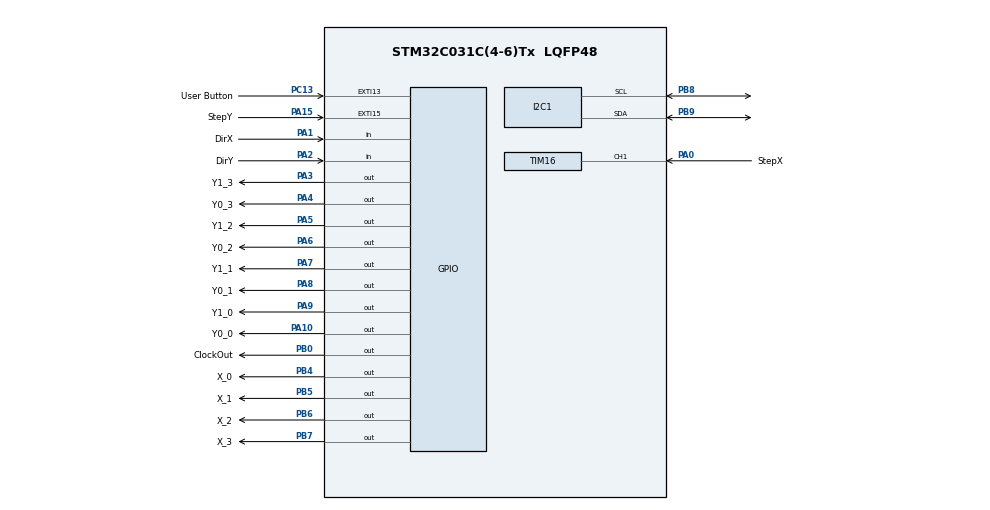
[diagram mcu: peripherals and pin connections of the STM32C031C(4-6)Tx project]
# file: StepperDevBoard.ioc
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I2C1.CustomTiming=Disabled
I2C1.NoStretchMode=I2C_NOSTRETCH_ENABLE
I2C1.OwnAddress=15
I2C1.Timing=0x20303E5D
Mcu.Family=STM32C0
Mcu.Name=STM32C031C(4-6)Tx
Mcu.Package=LQFP48
NVIC.EXTI4_15_IRQn=true\:0\:0\:false\:false\:true\:true\:true\:true
NVIC.I2C1_IRQn=true\:0\:0\:false\:false\:true\:true\:true\:true
NVIC.TIM14_IRQn=true\:0\:0\:false\:false\:true\:true\:true\:true
NVIC.TIM16_IRQn=true\:0\:0\:false\:false\:true\:true\:true\:true
PA0.GPIO_Label=StepX
PA0.GPIO_PuPd=GPIO_NOPULL
PA0.Signal=S_TIM16_CH1
PA1.GPIO_Label=DirX
PA1.Signal=GPIO_Input
PA10.GPIO_Label=Y0_0
PA10.GPIO_Speed=GPIO_SPEED_FREQ_HIGH
PA10.Signal=GPIO_Output
PA13.GPIO_Label=SWDIO
PA13.Mode=Serial_Wire
PA13.Signal=DEBUG_SWDIO
PA14-BOOT0.GPIO_Label=SWCLK
PA14-BOOT0.Mode=Serial_Wire
PA14-BOOT0.Signal=DEBUG_SWCLK
PA15.GPIO_Label=StepY
PA15.Signal=GPXTI15
PA2.GPIO_Label=DirY
PA2.Signal=GPIO_Input
PA3.GPIO_Label=Y1_3
PA3.GPIO_Speed=GPIO_SPEED_FREQ_HIGH
PA3.Signal=GPIO_Output
PA4.GPIO_Label=Y0_3
PA4.GPIO_Speed=GPIO_SPEED_FREQ_HIGH
PA4.Signal=GPIO_Output
PA5.GPIO_Label=Y1_2
PA5.GPIO_Speed=GPIO_SPEED_FREQ_HIGH
PA5.PinState=GPIO_PIN_RESET
PA5.Signal=GPIO_Output
PA6.GPIO_Label=Y0_2
PA6.GPIO_Speed=GPIO_SPEED_FREQ_HIGH
PA6.Signal=GPIO_Output
PA7.GPIO_Label=Y1_1
PA7.GPIO_Speed=GPIO_SPEED_FREQ_HIGH
PA7.Signal=GPIO_Output
PA8.GPIO_Label=Y0_1
PA8.GPIO_Speed=GPIO_SPEED_FREQ_HIGH
PA8.Signal=GPIO_Output
PA9.GPIO_Label=Y1_0
PA9.GPIO_Speed=GPIO_SPEED_FREQ_HIGH
PA9.Signal=GPIO_Output
PB0.GPIO_Label=ClockOut
PB0.Signal=GPIO_Output
PB4.GPIO_Label=X_0
PB4.GPIO_Speed=GPIO_SPEED_FREQ_HIGH
PB4.Signal=GPIO_Output
PB5.GPIO_Label=X_1
PB5.GPIO_Speed=GPIO_SPEED_FREQ_HIGH
PB5.Signal=GPIO_Output
PB6.GPIO_Label=X_2
PB6.GPIO_Speed=GPIO_SPEED_FREQ_HIGH
PB6.Signal=GPIO_Output
PB7.GPIO_Label=X_3
PB7.GPIO_Speed=GPIO_SPEED_FREQ_HIGH
PB7.Signal=GPIO_Output
PB8.GPIO_Pu=GPIO_NOPULL
PB8.GPIO_Speed=GPIO_SPEED_FREQ_HIGH
PB8.Mode=I2C
PB8.Signal=I2C1_SCL
PB9.GPIO_Pu=GPIO_NOPULL
PB9.GPIO_Speed=GPIO_SPEED_FREQ_HIGH
PB9.Mode=I2C
PB9.Signal=I2C1_SDA
PC13.GPIO_Label=User Button
PC13.Signal=GPXTI13
PC14-OSCX_IN\ (PC14).Mode=LSE-External-Oscillator
PC14-OSCX_IN\ (PC14).Signal=RCC_OSCX_IN
PC15-OSCX_OUT\ (PC15).Mode=LSE-External-Oscillator
PC15-OSCX_OUT\ (PC15).Signal=RCC_OSCX_OUT
PF0-OSC_IN\ (PF0).Mode=HSE-External-Oscillator
PF0-OSC_IN\ (PF0).Signal=RCC_OSC_IN
PF1-OSC_OUT\ (PF1).Mode=HSE-External-Oscillator
PF1-OSC_OUT\ (PF1).Signal=RCC_OSC_OUT
ProjectManager.HeapSize=0x200
ProjectManager.StackSize=0x400
ProjectManager.TargetToolchain=STM32CubeIDE
RCC.ADCFreq_Value=48000000
RCC.AHBFreq_Value=48000000
RCC.CortexFreq_Value=48000000
RCC.EXTERNAL_CLOCK_VALUE=12288000
RCC.HCLKFreq_Value=48000000
RCC.HSE_VALUE=48000000
RCC.HSISYSCLKDivider=RCC_HSI_DIV1
RCC.HSI_VALUE=48000000
RCC.SYSCLKFreq_VALUE=48000000
SH.S_TIM16_CH1.0=TIM16_CH1,Input_Capture1_from_TI1
TIM14.AutoReloadPreload=TIM_AUTORELOAD_PRELOAD_DISABLE
TIM14.ClockDivision=TIM_CLOCKDIVISION_DIV1
TIM14.Period=38400-1
TIM14.Prescaler=2-1
TIM16.Channel=TIM_CHANNEL_1
TIM16.ICPolarity_CH1=TIM_INPUTCHANNELPOLARITY_BOTHEDGE
TIM16.Prescaler=48-1
VP_TIM14_VS_ClockSourceINT.Mode=Enable_Timer
VP_TIM16_VS_ClockSourceINT.Mode=Enable_Timer
board=NUCLEO-C031C6

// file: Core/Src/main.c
/* USER CODE BEGIN Header */
/**
  ******************************************************************************
  * @file           : main.c
  * @brief          : Main program body
  ******************************************************************************
  * @attention
  *
  * Copyright (c) 2024 STMicroelectronics.
  * All rights reserved.
  *
  * This software is licensed under terms that can be found in the LICENSE file
  * in the root directory of this software component.
  * If no LICENSE file comes with this software, it is provided AS-IS.
  *
  ******************************************************************************
  */
/* USER CODE END Header */
#include "main.h"

I2C_HandleTypeDef hi2c1;

TIM_HandleTypeDef htim14;
TIM_HandleTypeDef htim16;

void SystemClock_Config(void);
static void MX_GPIO_Init(void);
static void MX_I2C1_Init(void);
static void MX_TIM14_Init(void);
static void MX_TIM16_Init(void);
/* USER CODE BEGIN PFP */
void mazeMain(void);
/* USER CODE END PFP */

int main(void)
{

  /* MCU Configuration--------------------------------------------------------*/

  /* Reset of all peripherals, Initializes the Flash interface and the Systick. */
  HAL_Init();

  /* Configure the system clock */
  SystemClock_Config();

  /* Initialize all configured peripherals */
  MX_GPIO_Init();
  MX_I2C1_Init();
  MX_TIM14_Init();
  MX_TIM16_Init();
  /* USER CODE BEGIN 2 */
  mazeMain();
  /* USER CODE END 2 */

  /* Infinite loop */
  while (1)
  {

  }
}

void SystemClock_Config(void)
{
  RCC_OscInitTypeDef RCC_OscInitStruct = {0};
  RCC_ClkInitTypeDef RCC_ClkInitStruct = {0};

  /** Initializes the RCC Oscillators according to the specified parameters
  * in the RCC_OscInitTypeDef structure.
  */
  RCC_OscInitStruct.OscillatorType = RCC_OSCILLATORTYPE_HSI;
  RCC_OscInitStruct.HSIState = RCC_HSI_ON;
  RCC_OscInitStruct.HSIDiv = RCC_HSI_DIV1;
  RCC_OscInitStruct.HSICalibrationValue = RCC_HSICALIBRATION_DEFAULT;
  if (HAL_RCC_OscConfig(&RCC_OscInitStruct) != HAL_OK)
  {
    Error_Handler();
  }

  /** Initializes the CPU, AHB and APB buses clocks
  */
  RCC_ClkInitStruct.ClockType = RCC_CLOCKTYPE_HCLK|RCC_CLOCKTYPE_SYSCLK
                              |RCC_CLOCKTYPE_PCLK1;
  RCC_ClkInitStruct.SYSCLKSource = RCC_SYSCLKSOURCE_HSI;
  RCC_ClkInitStruct.SYSCLKDivider = RCC_SYSCLK_DIV1;
  RCC_ClkInitStruct.AHBCLKDivider = RCC_HCLK_DIV1;
  RCC_ClkInitStruct.APB1CLKDivider = RCC_APB1_DIV1;

  if (HAL_RCC_ClockConfig(&RCC_ClkInitStruct, FLASH_LATENCY_1) != HAL_OK)
  {
    Error_Handler();
  }
}

static void MX_I2C1_Init(void)
{

  hi2c1.Instance = I2C1;
  hi2c1.Init.Timing = 0x20303E5D;
  hi2c1.Init.OwnAddress1 = 30;
  hi2c1.Init.AddressingMode = I2C_ADDRESSINGMODE_7BIT;
  hi2c1.Init.DualAddressMode = I2C_DUALADDRESS_DISABLE;
  hi2c1.Init.OwnAddress2 = 0;
  hi2c1.Init.OwnAddress2Masks = I2C_OA2_NOMASK;
  hi2c1.Init.GeneralCallMode = I2C_GENERALCALL_DISABLE;
  hi2c1.Init.NoStretchMode = I2C_NOSTRETCH_ENABLE;
  if (HAL_I2C_Init(&hi2c1) != HAL_OK)
  {
    Error_Handler();
  }

  /** Configure Analogue filter
  */
  if (HAL_I2CEx_ConfigAnalogFilter(&hi2c1, I2C_ANALOGFILTER_ENABLE) != HAL_OK)
  {
    Error_Handler();
  }

  /** Configure Digital filter
  */
  if (HAL_I2CEx_ConfigDigitalFilter(&hi2c1, 0) != HAL_OK)
  {
    Error_Handler();
  }

}

static void MX_TIM14_Init(void)
{

  htim14.Instance = TIM14;
  htim14.Init.Prescaler = 2-1;
  htim14.Init.CounterMode = TIM_COUNTERMODE_UP;
  htim14.Init.Period = 38400-1;
  htim14.Init.ClockDivision = TIM_CLOCKDIVISION_DIV1;
  htim14.Init.AutoReloadPreload = TIM_AUTORELOAD_PRELOAD_DISABLE;
  if (HAL_TIM_Base_Init(&htim14) != HAL_OK)
  {
    Error_Handler();
  }

}

static void MX_TIM16_Init(void)
{

  TIM_IC_InitTypeDef sConfigIC = {0};

  htim16.Instance = TIM16;
  htim16.Init.Prescaler = 48-1;
  htim16.Init.CounterMode = TIM_COUNTERMODE_UP;
  htim16.Init.Period = 65535;
  htim16.Init.ClockDivision = TIM_CLOCKDIVISION_DIV1;
  htim16.Init.RepetitionCounter = 0;
  htim16.Init.AutoReloadPreload = TIM_AUTORELOAD_PRELOAD_DISABLE;
  if (HAL_TIM_Base_Init(&htim16) != HAL_OK)
  {
    Error_Handler();
  }
  if (HAL_TIM_IC_Init(&htim16) != HAL_OK)
  {
    Error_Handler();
  }
  sConfigIC.ICPolarity = TIM_INPUTCHANNELPOLARITY_BOTHEDGE;
  sConfigIC.ICSelection = TIM_ICSELECTION_DIRECTTI;
  sConfigIC.ICPrescaler = TIM_ICPSC_DIV1;
  sConfigIC.ICFilter = 0;
  if (HAL_TIM_IC_ConfigChannel(&htim16, &sConfigIC, TIM_CHANNEL_1) != HAL_OK)
  {
    Error_Handler();
  }

}

static void MX_GPIO_Init(void)
{
  GPIO_InitTypeDef GPIO_InitStruct = {0};

  /* GPIO Ports Clock Enable */
  __HAL_RCC_GPIOC_CLK_ENABLE();
  __HAL_RCC_GPIOF_CLK_ENABLE();
  __HAL_RCC_GPIOA_CLK_ENABLE();
  __HAL_RCC_GPIOB_CLK_ENABLE();

  /*Configure GPIO pin Output Level */
  HAL_GPIO_WritePin(GPIOA, Y1_3_Pin|Y0_3_Pin|Y1_2_Pin|Y0_2_Pin
                          |Y1_1_Pin|Y0_1_Pin|Y1_0_Pin|Y0_0_Pin, GPIO_PIN_RESET);

  /*Configure GPIO pin Output Level */
  HAL_GPIO_WritePin(GPIOB, ClockOut_Pin|X_0_Pin|X_1_Pin|X_2_Pin
                          |X_3_Pin, GPIO_PIN_RESET);

  /*Configure GPIO pin : User_Button_Pin */
  GPIO_InitStruct.Pin = User_Button_Pin;
  GPIO_InitStruct.Mode = GPIO_MODE_IT_RISING;
  GPIO_InitStruct.Pull = GPIO_NOPULL;
  HAL_GPIO_Init(User_Button_GPIO_Port, &GPIO_InitStruct);

  /*Configure GPIO pins : DirX_Pin DirY_Pin */
  GPIO_InitStruct.Pin = DirX_Pin|DirY_Pin;
  GPIO_InitStruct.Mode = GPIO_MODE_INPUT;
  GPIO_InitStruct.Pull = GPIO_NOPULL;
  HAL_GPIO_Init(GPIOA, &GPIO_InitStruct);

  /*Configure GPIO pins : Y1_3_Pin Y0_3_Pin Y1_2_Pin Y0_2_Pin
                           Y1_1_Pin Y0_1_Pin Y1_0_Pin Y0_0_Pin */
  GPIO_InitStruct.Pin = Y1_3_Pin|Y0_3_Pin|Y1_2_Pin|Y0_2_Pin
                          |Y1_1_Pin|Y0_1_Pin|Y1_0_Pin|Y0_0_Pin;
  GPIO_InitStruct.Mode = GPIO_MODE_OUTPUT_PP;
  GPIO_InitStruct.Pull = GPIO_NOPULL;
  GPIO_InitStruct.Speed = GPIO_SPEED_FREQ_HIGH;
  HAL_GPIO_Init(GPIOA, &GPIO_InitStruct);

  /*Configure GPIO pin : ClockOut_Pin */
  GPIO_InitStruct.Pin = ClockOut_Pin;
  GPIO_InitStruct.Mode = GPIO_MODE_OUTPUT_PP;
  GPIO_InitStruct.Pull = GPIO_NOPULL;
  GPIO_InitStruct.Speed = GPIO_SPEED_FREQ_LOW;
  HAL_GPIO_Init(ClockOut_GPIO_Port, &GPIO_InitStruct);

  /*Configure GPIO pin : StepY_Pin */
  GPIO_InitStruct.Pin = StepY_Pin;
  GPIO_InitStruct.Mode = GPIO_MODE_IT_RISING;
  GPIO_InitStruct.Pull = GPIO_NOPULL;
  HAL_GPIO_Init(StepY_GPIO_Port, &GPIO_InitStruct);

  /*Configure GPIO pins : X_0_Pin X_1_Pin X_2_Pin X_3_Pin */
  GPIO_InitStruct.Pin = X_0_Pin|X_1_Pin|X_2_Pin|X_3_Pin;
  GPIO_InitStruct.Mode = GPIO_MODE_OUTPUT_PP;
  GPIO_InitStruct.Pull = GPIO_NOPULL;
  GPIO_InitStruct.Speed = GPIO_SPEED_FREQ_HIGH;
  HAL_GPIO_Init(GPIOB, &GPIO_InitStruct);

  /* EXTI interrupt init*/
  HAL_NVIC_SetPriority(EXTI4_15_IRQn, 0, 0);
  HAL_NVIC_EnableIRQ(EXTI4_15_IRQn);

}

void Error_Handler(void)
{
  __disable_irq();
  while (1)
  {
  }
}
